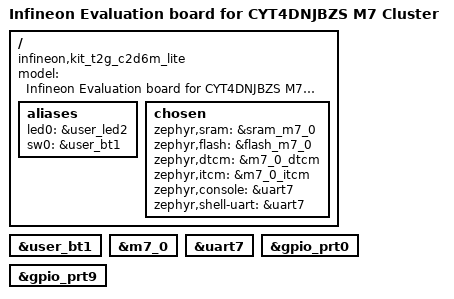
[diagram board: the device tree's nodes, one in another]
/*
 * Copyright (c) 2026 Linumiz
 * SPDX-License-Identifier: Apache-2.0
 */

/dts-v1/;
#include <arm/infineon/cat1c/traveo/cyt4dn/cyt4dn_m7.dtsi>
#include <arm/infineon/cat1c/traveo/cyt4dn/memory_partitions.dtsi>
#include "kit_t2g_c2d6m_lite_common.dtsi"
#include <common/freq.h>

/ {

	model = "Infineon Evaluation board for CYT4DNJBZS M7 Cluster";
	compatible = "infineon,kit_t2g_c2d6m_lite", "infineon,cyt4dn";

	aliases {
		led0 = &user_led2;
		sw0 = &user_bt1;
	};

	chosen {
		zephyr,sram = &sram_m7_0;
		zephyr,flash = &flash_m7_0;
		zephyr,dtcm = &m7_0_dtcm;
		zephyr,itcm = &m7_0_itcm;
		zephyr,console = &uart7;
		zephyr,shell-uart = &uart7;
	};
};

&user_bt1 {
	status = "okay";
};

&m7_0 {
	status = "okay";
};

&uart7 {
	status = "okay";
};

&gpio_prt0 {
	status = "okay";
};

&gpio_prt9 {
	status = "okay";
};
